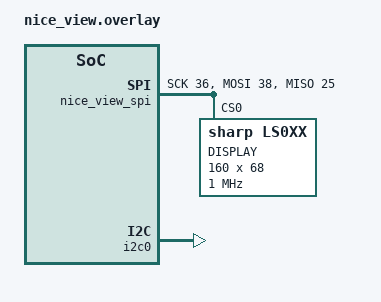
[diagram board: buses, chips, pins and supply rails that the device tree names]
/*
 * Patched nice_view.overlay for custom trackball I2C pins
 */

&nice_view_spi {
    status = "okay";

    /* Nice!View display on SPI using P1.04/P1.06 */
    sck-pin = <36>;   /* P1.04 */
    mosi-pin = <38>;  /* P1.06 */
    miso-pin = <25>;  /* keep default if used */

    nice_view: ls0xx@0 {
        compatible = "sharp,ls0xx";
        label = "DISPLAY";
        spi-max-frequency = <1000000>;
        reg = <0>;
        width = <160>;
        height = <68>;
    };
};

/ {
    chosen {
        zephyr,display = &nice_view;
    };
};

/* Force trackball I2C remap to P1.04/P1.06 */
&i2c0 {
    status = "okay";
};

/* Disable default Pro Micro I2C (if any) */
&pro_micro_i2c {
    status = "disabled";
};
